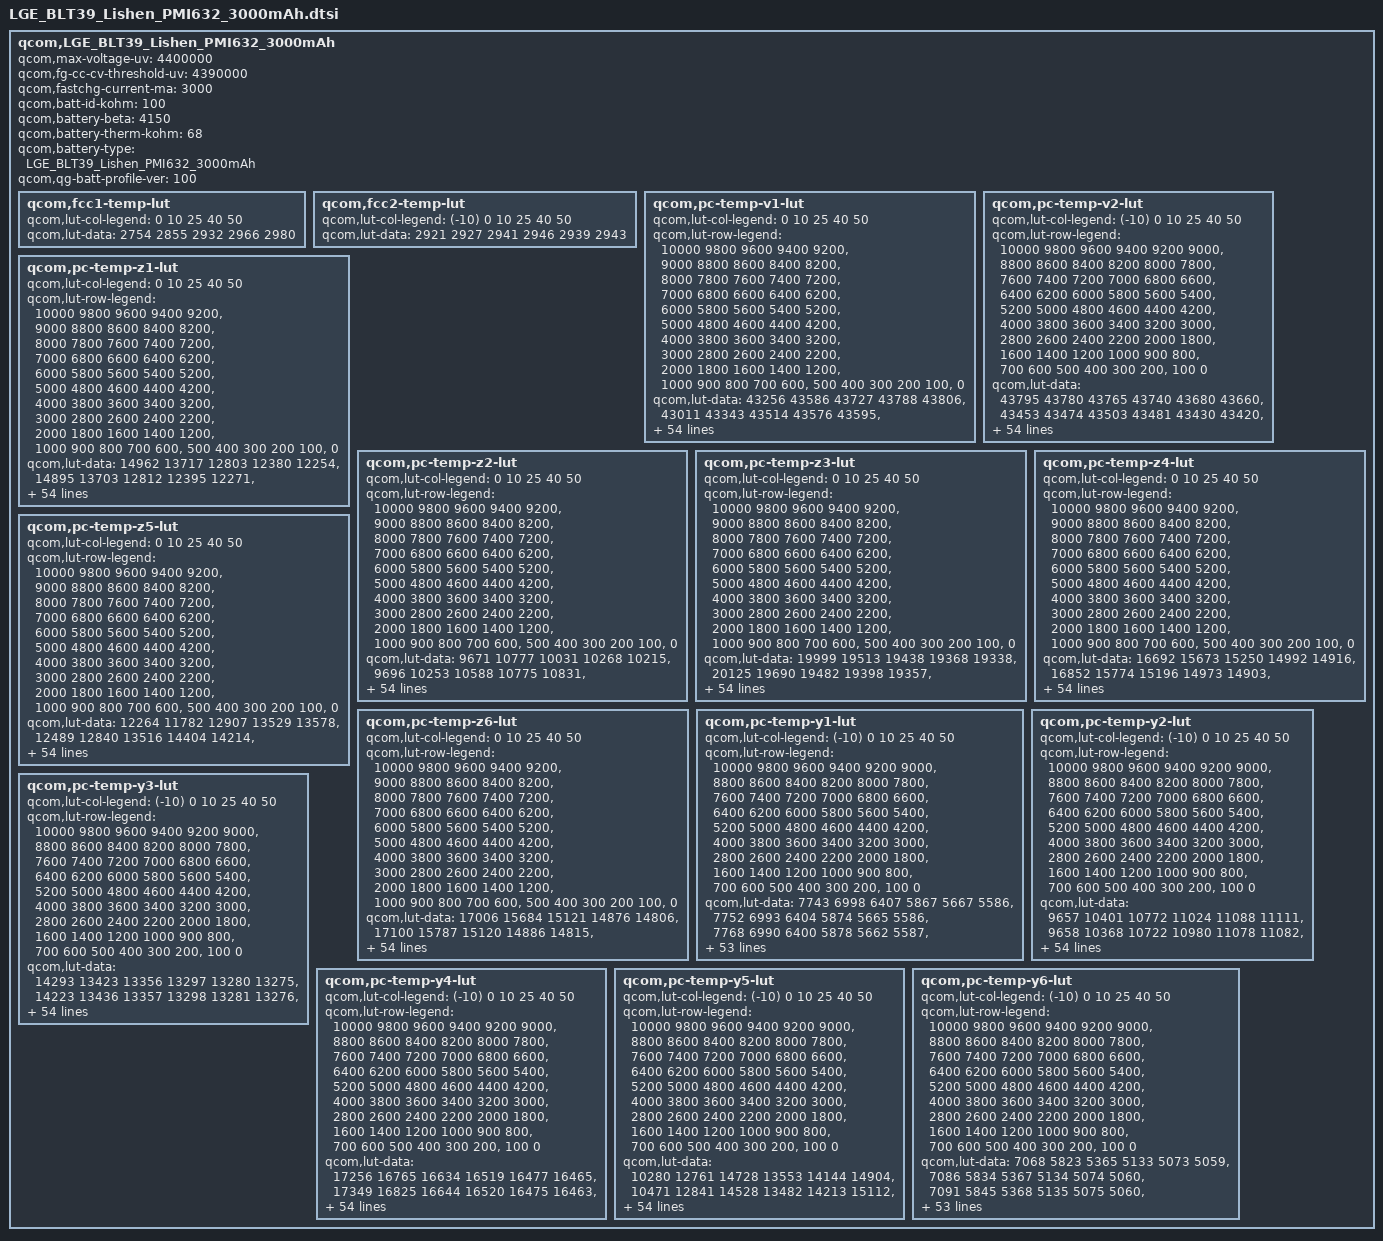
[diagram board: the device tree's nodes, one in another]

qcom,LGE_BLT39_Lishen_PMI632_3000mAh {
    /* 3840735_LGE_BLT39lish_3000mAh_averaged_MasterSlave_Feb14th2019 */
    qcom,max-voltage-uv = <4400000>;
    qcom,fg-cc-cv-threshold-uv = <4390000>;
    qcom,fastchg-current-ma = <3000>;
    qcom,batt-id-kohm = <100>;
    qcom,battery-beta = <4150>;
    qcom,battery-therm-kohm = <68>;
    qcom,battery-type = "LGE_BLT39_Lishen_PMI632_3000mAh";
    qcom,qg-batt-profile-ver = <100>;

	qcom,fcc1-temp-lut {
		qcom,lut-col-legend = <0 10 25 40 50>;
		qcom,lut-data = <2754 2855 2932 2966 2980>;
	};

	qcom,fcc2-temp-lut {
		qcom,lut-col-legend = <(-10) 0 10 25 40 50>;
		qcom,lut-data = <2921 2927 2941 2946 2939 2943>;
	};

	qcom,pc-temp-v1-lut {
		qcom,lut-col-legend = <0 10 25 40 50>;
		qcom,lut-row-legend = <10000 9800 9600 9400 9200>,
			<9000 8800 8600 8400 8200>,
			<8000 7800 7600 7400 7200>,
			<7000 6800 6600 6400 6200>,
			<6000 5800 5600 5400 5200>,
			<5000 4800 4600 4400 4200>,
			<4000 3800 3600 3400 3200>,
			<3000 2800 2600 2400 2200>,
			<2000 1800 1600 1400 1200>,
			<1000 900 800 700 600>,
			<500 400 300 200 100>,
			<0>;
		qcom,lut-data = <43256 43586 43727 43788 43806>,
			<43011 43343 43514 43576 43595>,
			<42778 43103 43291 43359 43380>,
			<42551 42865 43062 43136 43159>,
			<42326 42632 42829 42908 42933>,
			<42103 42401 42592 42678 42704>,
			<41883 42173 42355 42445 42472>,
			<41667 41950 42122 42212 42239>,
			<41454 41730 41894 41981 42010>,
			<41247 41513 41670 41751 41783>,
			<41048 41300 41451 41527 41559>,
			<40855 41097 41238 41310 41338>,
			<40668 40901 41030 41097 41121>,
			<40485 40712 40829 40892 40914>,
			<40309 40525 40634 40690 40713>,
			<40144 40341 40447 40499 40519>,
			<39990 40168 40268 40315 40332>,
			<39843 40008 40098 40139 40153>,
			<39696 39853 39946 39978 39985>,
			<39553 39699 39789 39824 39829>,
			<39416 39547 39595 39643 39656>,
			<39282 39385 39364 39410 39438>,
			<39154 39189 39158 39186 39219>,
			<39030 38974 38987 39019 39044>,
			<38907 38805 38837 38879 38891>,
			<38790 38679 38721 38755 38759>,
			<38682 38577 38627 38643 38645>,
			<38578 38501 38542 38542 38543>,
			<38488 38440 38456 38449 38448>,
			<38419 38385 38377 38361 38358>,
			<38362 38334 38307 38284 38276>,
			<38315 38287 38243 38214 38201>,
			<38277 38244 38187 38152 38132>,
			<38244 38206 38139 38097 38071>,
			<38213 38170 38097 38049 38019>,
			<38186 38138 38054 37999 37962>,
			<38155 38108 38016 37943 37894>,
			<38112 38068 37971 37882 37819>,
			<38049 37999 37905 37810 37743>,
			<37971 37908 37816 37728 37665>,
			<37874 37807 37717 37633 37575>,
			<37753 37688 37604 37522 37461>,
			<37616 37549 37472 37394 37329>,
			<37461 37385 37311 37235 37171>,
			<37302 37239 37170 37096 37034>,
			<37200 37143 37077 37006 36948>,
			<37161 37111 37052 36981 36924>,
			<37128 37084 37032 36964 36907>,
			<37097 37057 37012 36948 36894>,
			<37036 37012 36972 36908 36849>,
			<36839 36835 36762 36679 36602>,
			<36406 36404 36333 36258 36180>,
			<35833 35841 35774 35705 35625>,
			<35057 35077 35010 34950 34869>,
			<33794 33865 33819 33784 33706>,
			<30000 30000 30000 30000 30000>;
	};

	qcom,pc-temp-v2-lut {
		qcom,lut-col-legend = <(-10) 0 10 25 40 50>;
		qcom,lut-row-legend = <10000 9800 9600 9400 9200 9000>,
			<8800 8600 8400 8200 8000 7800>,
			<7600 7400 7200 7000 6800 6600>,
			<6400 6200 6000 5800 5600 5400>,
			<5200 5000 4800 4600 4400 4200>,
			<4000 3800 3600 3400 3200 3000>,
			<2800 2600 2400 2200 2000 1800>,
			<1600 1400 1200 1000 900 800>,
			<700 600 500 400 300 200>,
			<100 0>;
		qcom,lut-data = <43795 43780 43765 43740 43680 43660>,
			<43453 43474 43503 43481 43430 43420>,
			<43134 43187 43247 43229 43186 43184>,
			<42839 42922 43001 42987 42948 42951>,
			<42569 42677 42762 42754 42718 42722>,
			<42311 42440 42527 42523 42490 42493>,
			<42057 42203 42292 42291 42259 42263>,
			<41812 41968 42057 42059 42029 42033>,
			<41569 41740 41828 41830 41802 41807>,
			<41328 41518 41603 41605 41578 41583>,
			<41093 41300 41382 41383 41358 41363>,
			<40871 41088 41167 41168 41145 41149>,
			<40657 40882 40957 40958 40936 40938>,
			<40434 40677 40754 40755 40735 40736>,
			<40188 40471 40561 40555 40538 40541>,
			<39942 40263 40367 40363 40348 40352>,
			<39721 40044 40160 40182 40168 40172>,
			<39517 39816 39945 40010 39997 39997>,
			<39324 39598 39731 39830 39824 39824>,
			<39138 39395 39514 39640 39652 39657>,
			<38960 39204 39305 39444 39475 39484>,
			<38795 39020 39119 39234 39270 39280>,
			<38637 38844 38950 39009 39033 39043>,
			<38500 38686 38799 38824 38836 38847>,
			<38387 38553 38665 38689 38700 38710>,
			<38292 38434 38545 38575 38587 38597>,
			<38212 38322 38434 38468 38482 38490>,
			<38148 38213 38331 38369 38386 38391>,
			<38091 38119 38236 38278 38296 38300>,
			<38035 38047 38149 38191 38213 38216>,
			<37983 37988 38068 38112 38137 38139>,
			<37931 37934 37991 38040 38066 38067>,
			<37880 37883 37916 37977 38006 38004>,
			<37826 37834 37848 37914 37944 37937>,
			<37769 37785 37791 37850 37867 37854>,
			<37708 37737 37741 37784 37781 37758>,
			<37642 37684 37690 37713 37691 37658>,
			<37571 37624 37641 37634 37593 37549>,
			<37495 37556 37586 37553 37495 37444>,
			<37413 37480 37517 37474 37410 37356>,
			<37325 37391 37432 37395 37333 37277>,
			<37233 37290 37333 37302 37244 37184>,
			<37144 37164 37213 37180 37124 37064>,
			<37053 37030 37080 37052 37002 36941>,
			<36959 36909 36926 36916 36876 36820>,
			<36861 36807 36843 36871 36832 36782>,
			<36808 36765 36820 36853 36820 36769>,
			<36748 36721 36796 36833 36803 36751>,
			<36671 36667 36757 36799 36771 36718>,
			<36549 36575 36687 36699 36685 36610>,
			<36348 36382 36461 36416 36398 36293>,
			<36011 35995 36004 35900 35916 35797>,
			<35469 35402 35363 35233 35277 35144>,
			<34612 34545 34472 34266 34388 34228>,
			<33175 33107 33068 32862 32984 32797>,
			<28643 28622 29422 28756 29732 29552>;
	};

	qcom,pc-temp-z1-lut {
		qcom,lut-col-legend = <0 10 25 40 50>;
		qcom,lut-row-legend = <10000 9800 9600 9400 9200>,
			<9000 8800 8600 8400 8200>,
			<8000 7800 7600 7400 7200>,
			<7000 6800 6600 6400 6200>,
			<6000 5800 5600 5400 5200>,
			<5000 4800 4600 4400 4200>,
			<4000 3800 3600 3400 3200>,
			<3000 2800 2600 2400 2200>,
			<2000 1800 1600 1400 1200>,
			<1000 900 800 700 600>,
			<500 400 300 200 100>,
			<0>;
		qcom,lut-data = <14962 13717 12803 12380 12254>,
			<14895 13703 12812 12395 12271>,
			<14893 13710 12807 12403 12284>,
			<14898 13709 12801 12403 12291>,
			<14897 13705 12794 12404 12296>,
			<14894 13700 12787 12404 12299>,
			<14889 13692 12782 12404 12301>,
			<14881 13683 12782 12403 12302>,
			<14871 13678 12783 12402 12302>,
			<14859 13682 12783 12401 12303>,
			<14849 13691 12781 12400 12303>,
			<14838 13695 12777 12400 12303>,
			<14827 13685 12776 12400 12304>,
			<14808 13673 12777 12401 12304>,
			<14788 13671 12778 12402 12306>,
			<14779 13671 12779 12403 12307>,
			<14778 13671 12781 12405 12312>,
			<14781 13684 12783 12407 12316>,
			<14787 13704 12787 12409 12317>,
			<14799 13711 12793 12411 12316>,
			<14812 13707 12798 12414 12317>,
			<14828 13704 12803 12418 12320>,
			<14847 13714 12809 12422 12323>,
			<14856 13727 12814 12426 12327>,
			<14861 13736 12819 12429 12332>,
			<14865 13748 12826 12433 12336>,
			<14866 13762 12833 12438 12339>,
			<14864 13764 12840 12444 12343>,
			<14860 13762 12845 12448 12347>,
			<14855 13762 12850 12453 12351>,
			<14849 13771 12854 12457 12354>,
			<14848 13781 12858 12461 12357>,
			<14854 13785 12862 12465 12360>,
			<14866 13787 12868 12470 12363>,
			<14878 13789 12875 12476 12367>,
			<14905 13795 12882 12480 12370>,
			<14930 13805 12889 12483 12373>,
			<14933 13815 12896 12487 12376>,
			<14921 13824 12900 12490 12379>,
			<14912 13835 12904 12494 12382>,
			<14920 13845 12908 12498 12385>,
			<14932 13861 12914 12501 12388>,
			<14923 13868 12920 12505 12392>,
			<14905 13868 12927 12509 12395>,
			<14906 13867 12940 12513 12400>,
			<14885 13896 12944 12517 12401>,
			<14898 13871 12947 12518 12403>,
			<14921 13860 12945 12522 12403>,
			<14913 13863 12945 12523 12407>,
			<14906 13868 12955 12529 12409>,
			<14948 13891 12965 12535 12416>,
			<14968 13925 12986 12548 12427>,
			<14933 13968 13004 12567 12441>,
			<14956 13992 13050 12590 12462>,
			<14956 13992 13050 12590 12462>,
			<14956 13992 13050 12590 12462>;
	};

	qcom,pc-temp-z2-lut {
		qcom,lut-col-legend = <0 10 25 40 50>;
		qcom,lut-row-legend = <10000 9800 9600 9400 9200>,
			<9000 8800 8600 8400 8200>,
			<8000 7800 7600 7400 7200>,
			<7000 6800 6600 6400 6200>,
			<6000 5800 5600 5400 5200>,
			<5000 4800 4600 4400 4200>,
			<4000 3800 3600 3400 3200>,
			<3000 2800 2600 2400 2200>,
			<2000 1800 1600 1400 1200>,
			<1000 900 800 700 600>,
			<500 400 300 200 100>,
			<0>;
		qcom,lut-data = <9671 10777 10031 10268 10215>,
			<9696 10253 10588 10775 10831>,
			<9702 9913 10638 11001 11158>,
			<9705 9833 10485 10911 11107>,
			<9706 9812 10322 10748 10926>,
			<9700 9796 10173 10670 10853>,
			<9691 9784 10047 10640 10837>,
			<9684 9774 10042 10603 10817>,
			<9677 9769 10162 10484 10778>,
			<9669 9774 10262 10325 10721>,
			<9660 9785 10281 10302 10702>,
			<9651 9807 10293 10431 10711>,
			<9645 9866 10296 10545 10722>,
			<9641 9909 10281 10570 10640>,
			<9638 9894 10268 10592 10409>,
			<9645 9859 10278 10614 10314>,
			<9699 9852 10300 10660 10316>,
			<9749 9868 10307 10694 10320>,
			<9738 9888 10229 10589 10331>,
			<9686 9902 10145 10352 10357>,
			<9654 9913 10141 10272 10371>,
			<9657 9922 10151 10291 10365>,
			<9664 9930 10154 10318 10356>,
			<9672 9937 10126 10352 10358>,
			<9682 9943 10089 10393 10369>,
			<9696 9949 10091 10404 10363>,
			<9708 9952 10129 10362 10300>,
			<9722 9952 10152 10307 10227>,
			<9735 9950 10130 10273 10205>,
			<9747 9948 10096 10246 10195>,
			<9759 9951 10088 10228 10191>,
			<9770 9956 10093 10215 10203>,
			<9780 9962 10099 10207 10225>,
			<9791 9967 10109 10206 10248>,
			<9804 9974 10121 10208 10279>,
			<9822 9981 10133 10214 10313>,
			<9841 9991 10145 10264 10365>,
			<9862 10000 10156 10329 10413>,
			<9886 10011 10169 10358 10421>,
			<9904 10021 10183 10384 10413>,
			<9831 10027 10196 10394 10410>,
			<9696 10029 10209 10370 10429>,
			<9627 10035 10216 10347 10445>,
			<9614 10051 10215 10344 10443>,
			<10127 10191 10244 10377 10454>,
			<12074 10313 10264 10403 10458>,
			<10518 10457 10259 10370 10496>,
			<10377 10558 10263 10421 10452>,
			<10513 10600 10253 10429 10496>,
			<10772 10645 10282 10483 10578>,
			<10680 10605 10436 10435 10399>,
			<9724 10364 10495 10373 10311>,
			<9463 10198 10534 10410 10294>,
			<9304 10026 10385 10349 10182>,
			<9304 10026 10385 10349 10182>,
			<9304 10026 10385 10349 10182>;
	};

	qcom,pc-temp-z3-lut {
		qcom,lut-col-legend = <0 10 25 40 50>;
		qcom,lut-row-legend = <10000 9800 9600 9400 9200>,
			<9000 8800 8600 8400 8200>,
			<8000 7800 7600 7400 7200>,
			<7000 6800 6600 6400 6200>,
			<6000 5800 5600 5400 5200>,
			<5000 4800 4600 4400 4200>,
			<4000 3800 3600 3400 3200>,
			<3000 2800 2600 2400 2200>,
			<2000 1800 1600 1400 1200>,
			<1000 900 800 700 600>,
			<500 400 300 200 100>,
			<0>;
		qcom,lut-data = <19999 19513 19438 19368 19338>,
			<20125 19690 19482 19398 19357>,
			<20113 19791 19513 19420 19376>,
			<20090 19823 19544 19442 19397>,
			<20078 19835 19559 19461 19420>,
			<20071 19841 19558 19464 19427>,
			<20067 19839 19557 19461 19426>,
			<20071 19827 19557 19456 19422>,
			<20089 19813 19561 19445 19415>,
			<20102 19799 19563 19429 19403>,
			<20103 19785 19558 19422 19398>,
			<20101 19777 19552 19421 19398>,
			<20098 19775 19545 19421 19397>,
			<20086 19773 19533 19420 19387>,
			<20069 19756 19523 19419 19361>,
			<20060 19727 19520 19416 19350>,
			<20057 19706 19518 19409 19349>,
			<20056 19689 19513 19401 19348>,
			<20042 19674 19490 19389 19346>,
			<20004 19672 19467 19374 19344>,
			<19981 19680 19476 19370 19343>,
			<19985 19692 19512 19386 19345>,
			<19998 19711 19530 19400 19351>,
			<20008 19734 19514 19397 19359>,
			<20019 19742 19492 19389 19372>,
			<20027 19741 19487 19388 19380>,
			<20029 19738 19488 19408 19383>,
			<20029 19734 19491 19428 19384>,
			<20028 19726 19502 19429 19383>,
			<20022 19718 19517 19425 19380>,
			<20005 19712 19520 19420 19376>,
			<19987 19706 19518 19411 19373>,
			<19969 19701 19516 19402 19369>,
			<19950 19696 19511 19395 19365>,
			<19929 19691 19505 19390 19359>,
			<19904 19685 19501 19389 19357>,
			<19878 19678 19498 19389 19357>,
			<19857 19672 19495 19389 19358>,
			<19840 19668 19490 19389 19358>,
			<19819 19663 19485 19387 19354>,
			<19713 19656 19481 19385 19352>,
			<19553 19644 19477 19379 19352>,
			<19423 19632 19472 19374 19353>,
			<19268 19619 19467 19372 19353>,
			<19262 19550 19450 19365 19346>,
			<19258 19464 19444 19360 19343>,
			<19261 19384 19431 19360 19342>,
			<19260 19337 19430 19359 19341>,
			<19260 19327 19414 19350 19325>,
			<19260 19321 19408 19338 19319>,
			<19261 19337 19383 19357 19342>,
			<19264 19334 19367 19358 19347>,
			<19270 19329 19350 19344 19348>,
			<19278 19333 19370 19352 19355>,
			<19278 19333 19370 19352 19355>,
			<19278 19333 19370 19352 19355>;
	};

	qcom,pc-temp-z4-lut {
		qcom,lut-col-legend = <0 10 25 40 50>;
		qcom,lut-row-legend = <10000 9800 9600 9400 9200>,
			<9000 8800 8600 8400 8200>,
			<8000 7800 7600 7400 7200>,
			<7000 6800 6600 6400 6200>,
			<6000 5800 5600 5400 5200>,
			<5000 4800 4600 4400 4200>,
			<4000 3800 3600 3400 3200>,
			<3000 2800 2600 2400 2200>,
			<2000 1800 1600 1400 1200>,
			<1000 900 800 700 600>,
			<500 400 300 200 100>,
			<0>;
		qcom,lut-data = <16692 15673 15250 14992 14916>,
			<16852 15774 15196 14973 14903>,
			<16715 15610 15128 14946 14884>,
			<16427 15455 15042 14905 14856>,
			<16191 15330 14973 14857 14817>,
			<16016 15224 14932 14820 14787>,
			<15860 15146 14899 14789 14763>,
			<15724 15085 14864 14769 14747>,
			<15600 15033 14820 14768 14742>,
			<15495 14986 14784 14773 14739>,
			<15409 14944 14764 14771 14734>,
			<15337 14906 14750 14753 14721>,
			<15278 14866 14744 14733 14708>,
			<15233 14843 14743 14721 14711>,
			<15193 14848 14742 14708 14725>,
			<15146 14863 14735 14701 14729>,
			<15071 14866 14724 14697 14720>,
			<15012 14862 14720 14694 14708>,
			<15010 14856 14730 14694 14701>,
			<15037 14846 14747 14702 14695>,
			<15048 14828 14770 14721 14696>,
			<15025 14817 14812 14793 14760>,
			<14993 14849 14855 14859 14834>,
			<14974 14924 14904 14874 14840>,
			<14962 14962 14943 14882 14832>,
			<14953 14972 14942 14881 14821>,
			<14954 14975 14910 14840 14801>,
			<14963 14966 14873 14790 14778>,
			<14972 14942 14838 14768 14761>,
			<14971 14917 14803 14752 14747>,
			<14967 14898 14784 14742 14734>,
			<14962 14881 14772 14734 14722>,
			<14954 14866 14765 14728 14712>,
			<14943 14852 14761 14723 14706>,
			<14932 14840 14758 14718 14701>,
			<14921 14826 14757 14717 14699>,
			<14909 14812 14756 14728 14717>,
			<14896 14804 14756 14742 14741>,
			<14881 14800 14760 14746 14744>,
			<14870 14798 14769 14748 14739>,
			<14958 14792 14772 14749 14732>,
			<15114 14781 14754 14739 14720>,
			<15227 14773 14740 14732 14712>,
			<15355 14765 14735 14734 14713>,
			<15215 14758 14719 14725 14709>,
			<15204 14824 14701 14711 14698>,
			<15197 14905 14699 14695 14684>,
			<15190 14952 14683 14674 14665>,
			<15183 14955 14689 14664 14656>,
			<15175 14957 14693 14675 14662>,
			<15179 14943 14742 14685 14666>,
			<15213 14969 14766 14686 14663>,
			<15246 14987 14788 14702 14662>,
			<15284 15005 14772 14695 14656>,
			<15284 15005 14772 14695 14656>,
			<15284 15005 14772 14695 14656>;
	};

	qcom,pc-temp-z5-lut {
		qcom,lut-col-legend = <0 10 25 40 50>;
		qcom,lut-row-legend = <10000 9800 9600 9400 9200>,
			<9000 8800 8600 8400 8200>,
			<8000 7800 7600 7400 7200>,
			<7000 6800 6600 6400 6200>,
			<6000 5800 5600 5400 5200>,
			<5000 4800 4600 4400 4200>,
			<4000 3800 3600 3400 3200>,
			<3000 2800 2600 2400 2200>,
			<2000 1800 1600 1400 1200>,
			<1000 900 800 700 600>,
			<500 400 300 200 100>,
			<0>;
		qcom,lut-data = <12264 11782 12907 13529 13578>,
			<12489 12840 13516 14404 14214>,
			<12622 13689 13966 15100 14922>,
			<12733 14244 14593 15860 15877>,
			<12872 14649 15203 16862 17216>,
			<13059 14969 15640 17564 18253>,
			<13283 15204 16066 18308 19242>,
			<13566 15372 16780 18751 19891>,
			<13965 15584 18229 18387 19644>,
			<14355 16012 19529 17636 18895>,
			<14668 16609 20255 17481 18654>,
			<14946 17201 20795 17981 19649>,
			<15105 18077 20897 18741 20676>,
			<15181 18629 20661 19688 19743>,
			<15238 18276 20445 20754 16952>,
			<15385 17656 20863 21328 15805>,
			<16114 17465 21938 21515 16150>,
			<16755 17362 22266 21554 16670>,
			<16524 17226 20286 20446 17111>,
			<15724 17464 18140 17988 17561>,
			<15370 19206 20763 17499 17719>,
			<15970 21754 30080 19538 17444>,
			<17142 25948 34729 21333 16955>,
			<18512 31242 29025 19847 16300>,
			<20362 32953 21078 16026 15344>,
			<22426 31300 18577 14678 14941>,
			<24186 28837 17528 15764 15275>,
			<25974 26999 17132 17265 15869>,
			<27141 25258 18155 18383 16462>,
			<27179 24212 20233 19416 17163>,
			<26671 23868 22047 20052 17988>,
			<26073 23738 23829 20382 19072>,
			<25248 23872 25312 20686 20248>,
			<24115 24274 26343 21239 21308>,
			<23028 24707 27150 22137 22380>,
			<21848 24954 27587 22721 22829>,
			<20829 25130 27874 23007 22399>,
			<20283 25397 28026 23177 21580>,
			<19964 26282 27402 22868 20666>,
			<19565 27241 25705 21551 19454>,
			<17719 26943 24708 20329 18866>,
			<15044 24655 24452 19579 19037>,
			<13057 23333 24073 18839 19184>,
			<10740 22637 22857 17843 18377>,
			<10920 19806 22228 17491 17462>,
			<10871 14385 22765 17436 17386>,
			<10867 12278 20374 18262 18088>,
			<10865 11513 20158 19682 20107>,
			<10865 11417 17651 19193 18371>,
			<10878 11364 17209 16421 16837>,
			<10884 11559 14326 16414 16885>,
			<10837 11420 13177 15975 17290>,
			<10752 11291 12484 14072 17052>,
			<10701 11219 12878 14438 18093>,
			<10701 11219 12878 14438 18093>,
			<10701 11219 12878 14438 18093>;
	};

	qcom,pc-temp-z6-lut {
		qcom,lut-col-legend = <0 10 25 40 50>;
		qcom,lut-row-legend = <10000 9800 9600 9400 9200>,
			<9000 8800 8600 8400 8200>,
			<8000 7800 7600 7400 7200>,
			<7000 6800 6600 6400 6200>,
			<6000 5800 5600 5400 5200>,
			<5000 4800 4600 4400 4200>,
			<4000 3800 3600 3400 3200>,
			<3000 2800 2600 2400 2200>,
			<2000 1800 1600 1400 1200>,
			<1000 900 800 700 600>,
			<500 400 300 200 100>,
			<0>;
		qcom,lut-data = <17006 15684 15121 14876 14806>,
			<17100 15787 15120 14886 14815>,
			<17021 15753 15110 14890 14820>,
			<16854 15711 15085 14884 14819>,
			<16720 15654 15059 14872 14814>,
			<16620 15593 15039 14861 14809>,
			<16534 15546 15020 14846 14799>,
			<16466 15505 15003 14833 14789>,
			<16409 15469 14985 14825 14781>,
			<16360 15435 14970 14819 14775>,
			<16315 15406 14959 14812 14769>,
			<16274 15384 14950 14804 14763>,
			<16236 15367 14942 14796 14758>,
			<16198 15353 14935 14790 14752>,
			<16163 15343 14928 14785 14745>,
			<16132 15333 14923 14779 14739>,
			<16098 15325 14918 14774 14734>,
			<16075 15314 14914 14769 14730>,
			<16068 15305 14908 14765 14726>,
			<16064 15304 14904 14761 14723>,
			<16062 15304 14915 14763 14722>,
			<16061 15305 14956 14803 14751>,
			<16060 15328 14985 14841 14787>,
			<16060 15376 14999 14846 14797>,
			<16063 15401 15007 14848 14801>,
			<16068 15407 15005 14848 14802>,
			<16074 15411 14993 14842 14797>,
			<16085 15408 14982 14832 14787>,
			<16092 15396 14974 14824 14779>,
			<16090 15384 14968 14816 14772>,
			<16082 15375 14963 14808 14765>,
			<16074 15367 14958 14800 14758>,
			<16067 15360 14954 14794 14752>,
			<16061 15354 14950 14788 14746>,
			<16053 15349 14947 14784 14741>,
			<16043 15344 14946 14782 14739>,
			<16032 15339 14946 14788 14748>,
			<16023 15337 14946 14795 14759>,
			<16015 15339 14947 14796 14760>,
			<16009 15342 14950 14797 14756>,
			<16003 15341 14951 14797 14752>,
			<15998 15336 14943 14790 14748>,
			<15989 15333 14937 14785 14745>,
			<15969 15331 14935 14785 14746>,
			<15915 15302 14921 14779 14742>,
			<15918 15296 14914 14771 14735>,
			<15918 15293 14906 14764 14729>,
			<15919 15292 14901 14755 14720>,
			<15922 15293 14897 14746 14708>,
			<15930 15296 14899 14745 14708>,
			<15950 15312 14912 14761 14724>,
			<15985 15337 14920 14765 14727>,
			<16029 15362 14929 14769 14731>,
			<16085 15401 14943 14775 14736>,
			<16085 15401 14943 14775 14736>,
			<16085 15401 14943 14775 14736>;
	};

	qcom,pc-temp-y1-lut {
		qcom,lut-col-legend = <(-10) 0 10 25 40 50>;
		qcom,lut-row-legend = <10000 9800 9600 9400 9200 9000>,
			<8800 8600 8400 8200 8000 7800>,
			<7600 7400 7200 7000 6800 6600>,
			<6400 6200 6000 5800 5600 5400>,
			<5200 5000 4800 4600 4400 4200>,
			<4000 3800 3600 3400 3200 3000>,
			<2800 2600 2400 2200 2000 1800>,
			<1600 1400 1200 1000 900 800>,
			<700 600 500 400 300 200>,
			<100 0>;
		qcom,lut-data = <7743 6998 6407 5867 5667 5586>,
			<7752 6993 6404 5874 5665 5586>,
			<7768 6990 6400 5878 5662 5587>,
			<7785 6988 6395 5880 5659 5586>,
			<7799 6988 6390 5881 5657 5586>,
			<7806 6989 6388 5881 5656 5586>,
			<7806 6994 6387 5879 5654 5585>,
			<7804 7003 6386 5876 5653 5584>,
			<7803 7008 6386 5873 5653 5584>,
			<7803 7016 6389 5872 5653 5584>,
			<7802 7022 6391 5870 5654 5584>,
			<7796 7017 6390 5871 5652 5583>,
			<7784 7002 6389 5871 5650 5583>,
			<7779 6996 6388 5871 5649 5583>,
			<7797 6998 6385 5870 5650 5584>,
			<7817 7002 6382 5870 5651 5586>,
			<7814 7009 6383 5870 5651 5586>,
			<7791 7029 6383 5870 5651 5585>,
			<7775 7039 6384 5872 5651 5584>,
			<7781 7037 6384 5875 5651 5585>,
			<7790 7033 6385 5878 5652 5586>,
			<7790 7029 6387 5878 5653 5587>,
			<7777 7025 6396 5879 5654 5588>,
			<7767 7024 6403 5879 5656 5589>,
			<7775 7029 6409 5882 5658 5590>,
			<7791 7035 6413 5886 5660 5591>,
			<7794 7040 6415 5888 5661 5592>,
			<7778 7043 6415 5890 5662 5595>,
			<7763 7045 6414 5891 5663 5597>,
			<7774 7040 6412 5895 5665 5597>,
			<7802 7031 6408 5899 5667 5598>,
			<7813 7029 6407 5901 5669 5599>,
			<7816 7047 6404 5901 5672 5603>,
			<7817 7063 6401 5901 5675 5606>,
			<7813 7057 6402 5905 5678 5607>,
			<7805 7044 6405 5913 5681 5608>,
			<7796 7034 6408 5915 5683 5608>,
			<7778 7022 6415 5917 5685 5611>,
			<7759 7011 6422 5919 5687 5614>,
			<7757 7013 6422 5923 5689 5616>,
			<7767 7022 6420 5929 5691 5618>,
			<7775 7028 6421 5933 5693 5619>,
			<7778 7028 6428 5934 5695 5620>,
			<7784 7030 6433 5935 5697 5621>,
			<7780 7019 6434 5938 5701 5626>,
			<7778 7025 6434 5942 5704 5626>,
			<7782 7039 6435 5947 5705 5627>,
			<7798 7044 6438 5951 5706 5630>,
			<7824 7039 6442 5951 5707 5630>,
			<7802 7067 6446 5950 5707 5632>,
			<7824 7067 6463 5956 5712 5633>,
			<7912 7069 6481 5971 5720 5642>,
			<8009 7120 6496 5998 5730 5653>,
			<8164 7203 6531 6015 5748 5667>,
			<8164 7203 6531 6015 5748 5667>,
			<8164 7203 6531 6015 5748 5667>;
	};

	qcom,pc-temp-y2-lut {
		qcom,lut-col-legend = <(-10) 0 10 25 40 50>;
		qcom,lut-row-legend = <10000 9800 9600 9400 9200 9000>,
			<8800 8600 8400 8200 8000 7800>,
			<7600 7400 7200 7000 6800 6600>,
			<6400 6200 6000 5800 5600 5400>,
			<5200 5000 4800 4600 4400 4200>,
			<4000 3800 3600 3400 3200 3000>,
			<2800 2600 2400 2200 2000 1800>,
			<1600 1400 1200 1000 900 800>,
			<700 600 500 400 300 200>,
			<100 0>;
		qcom,lut-data = <9657 10401 10772 11024 11088 11111>,
			<9658 10368 10722 10980 11078 11082>,
			<9658 10346 10668 10938 11052 11041>,
			<9659 10331 10615 10899 11018 10997>,
			<9660 10323 10569 10864 10982 10960>,
			<9661 10320 10537 10835 10952 10938>,
			<9661 10324 10516 10813 10918 10931>,
			<9662 10335 10500 10794 10881 10926>,
			<9663 10348 10494 10779 10873 10925>,
			<9663 10367 10493 10765 10880 10916>,
			<9663 10388 10494 10754 10889 10909>,
			<9663 10410 10501 10741 10893 10899>,
			<9663 10433 10517 10730 10893 10879>,
			<9663 10456 10537 10724 10890 10876>,
			<9662 10481 10567 10723 10871 10904>,
			<9662 10502 10597 10724 10853 10934>,
			<9661 10512 10616 10738 10860 10938>,
			<9660 10518 10630 10772 10893 10928>,
			<9659 10525 10644 10796 10933 10932>,
			<9659 10538 10660 10807 10999 11024>,
			<9659 10552 10677 10818 11060 11127>,
			<9659 10514 10692 10837 11056 11134>,
			<9659 10302 10708 10867 11010 11112>,
			<9658 10160 10723 10887 10983 11096>,
			<9658 10297 10743 10892 11000 11094>,
			<9657 10530 10761 10897 11027 11096>,
			<9657 10547 10770 10905 11044 11103>,
			<9656 10189 10776 10919 11078 11141>,
			<9656 9865 10779 10926 11100 11169>,
			<9655 9818 10777 10922 11082 11185>,
			<9655 9796 10773 10913 11052 11208>,
			<9655 9800 10771 10908 11059 11213>,
			<9654 9966 10772 10907 11126 11223>,
			<9654 10147 10774 10907 11180 11232>,
			<9654 10088 10772 10904 11149 11235>,
			<9653 9836 10770 10897 11076 11236>,
			<9653 9696 10764 10888 11043 11231>,
			<9653 9681 10736 10871 11033 11197>,
			<9653 9673 10700 10857 11029 11165>,
			<9653 9667 10673 10866 11044 11172>,
			<9653 9664 10647 10888 11079 11195>,
			<9653 9661 10612 10898 11107 11203>,
			<9652 9658 10562 10897 11129 11184>,
			<9652 9656 10493 10883 11136 11154>,
			<9652 9655 10328 10817 11055 11100>,
			<9652 9654 10202 10821 11046 11039>,
			<9652 9653 10223 10849 11047 11018>,
			<9652 9653 10280 10860 11010 11014>,
			<9652 9653 10181 10835 10982 10948>,
			<9651 9652 10201 10829 10938 10917>,
			<9651 9651 9811 10776 10974 10930>,
			<9650 9651 9702 10744 10896 10834>,
			<9648 9650 9668 10654 10853 10783>,
			<9647 9649 9658 10556 10758 10702>,
			<9647 9649 9658 10556 10758 10702>,
			<9647 9649 9658 10556 10758 10702>;
	};

	qcom,pc-temp-y3-lut {
		qcom,lut-col-legend = <(-10) 0 10 25 40 50>;
		qcom,lut-row-legend = <10000 9800 9600 9400 9200 9000>,
			<8800 8600 8400 8200 8000 7800>,
			<7600 7400 7200 7000 6800 6600>,
			<6400 6200 6000 5800 5600 5400>,
			<5200 5000 4800 4600 4400 4200>,
			<4000 3800 3600 3400 3200 3000>,
			<2800 2600 2400 2200 2000 1800>,
			<1600 1400 1200 1000 900 800>,
			<700 600 500 400 300 200>,
			<100 0>;
		qcom,lut-data = <14293 13423 13356 13297 13280 13275>,
			<14223 13436 13357 13298 13281 13276>,
			<14155 13451 13360 13300 13282 13278>,
			<14092 13466 13362 13301 13283 13279>,
			<14037 13478 13365 13303 13284 13280>,
			<13991 13487 13367 13304 13285 13281>,
			<13958 13492 13370 13305 13286 13282>,
			<13930 13496 13372 13305 13287 13283>,
			<13899 13496 13373 13306 13287 13283>,
			<13860 13496 13375 13307 13287 13283>,
			<13827 13494 13377 13308 13286 13283>,
			<13814 13491 13378 13311 13288 13283>,
			<13805 13487 13381 13317 13293 13283>,
			<13794 13482 13383 13319 13295 13283>,
			<13763 13479 13386 13319 13293 13286>,
			<13724 13475 13389 13319 13292 13290>,
			<13693 13468 13388 13320 13293 13289>,
			<13664 13457 13383 13323 13297 13288>,
			<13647 13447 13378 13324 13299 13288>,
			<13640 13439 13372 13324 13301 13291>,
			<13636 13431 13366 13323 13302 13295>,
			<13631 13418 13359 13319 13299 13293>,
			<13626 13394 13352 13309 13289 13284>,
			<13624 13378 13348 13303 13282 13278>,
			<13629 13383 13345 13304 13281 13277>,
			<13644 13392 13342 13306 13281 13276>,
			<13664 13384 13342 13305 13281 13276>,
			<13696 13321 13341 13304 13283 13277>,
			<13737 13269 13341 13303 13284 13278>,
			<13782 13267 13341 13303 13284 13278>,
			<13835 13269 13342 13302 13284 13278>,
			<13894 13274 13342 13303 13284 13278>,
			<13959 13313 13338 13306 13286 13278>,
			<14030 13360 13335 13309 13287 13278>,
			<14108 13378 13334 13309 13287 13278>,
			<14193 13390 13335 13308 13286 13278>,
			<14281 13401 13336 13308 13285 13277>,
			<14374 13413 13340 13307 13284 13277>,
			<14468 13428 13345 13305 13282 13277>,
			<14555 13455 13348 13305 13282 13276>,
			<14637 13506 13350 13304 13281 13276>,
			<14717 13570 13352 13303 13281 13276>,
			<14795 13646 13355 13302 13281 13277>,
			<14878 13747 13357 13303 13282 13278>,
			<14979 13897 13348 13304 13283 13277>,
			<15121 14123 13357 13306 13284 13278>,
			<15212 14249 13366 13306 13284 13280>,
			<15198 14277 13371 13306 13287 13284>,
			<15279 14412 13379 13312 13293 13289>,
			<15531 14636 13399 13313 13294 13287>,
			<15868 14922 13408 13313 13288 13284>,
			<16540 15276 13447 13310 13289 13286>,
			<18625 15715 13554 13323 13291 13289>,
			<25299 17056 13812 13334 13298 13291>,
			<25299 17056 13812 13334 13298 13291>,
			<25299 17056 13812 13334 13298 13291>;
	};

	qcom,pc-temp-y4-lut {
		qcom,lut-col-legend = <(-10) 0 10 25 40 50>;
		qcom,lut-row-legend = <10000 9800 9600 9400 9200 9000>,
			<8800 8600 8400 8200 8000 7800>,
			<7600 7400 7200 7000 6800 6600>,
			<6400 6200 6000 5800 5600 5400>,
			<5200 5000 4800 4600 4400 4200>,
			<4000 3800 3600 3400 3200 3000>,
			<2800 2600 2400 2200 2000 1800>,
			<1600 1400 1200 1000 900 800>,
			<700 600 500 400 300 200>,
			<100 0>;
		qcom,lut-data = <17256 16765 16634 16519 16477 16465>,
			<17349 16825 16644 16520 16475 16463>,
			<17498 16892 16655 16521 16475 16462>,
			<17659 16958 16666 16522 16475 16461>,
			<17793 17015 16676 16524 16477 16461>,
			<17857 17052 16685 16527 16479 16461>,
			<17851 17070 16691 16531 16481 16462>,
			<17835 17082 16698 16537 16485 16465>,
			<17820 17095 16706 16544 16489 16469>,
			<17806 17109 16719 16551 16497 16473>,
			<17789 17125 16735 16559 16503 16479>,
			<17759 17149 16755 16564 16507 16486>,
			<17711 17178 16782 16570 16509 16495>,
			<17652 17188 16811 16579 16513 16501>,
			<17572 17182 16855 16597 16526 16505>,
			<17488 17168 16888 16623 16543 16509>,
			<17431 17136 16884 16655 16559 16519>,
			<17389 17062 16862 16697 16575 16536>,
			<17342 16990 16832 16716 16594 16555>,
			<17275 16929 16771 16717 16629 16586>,
			<17200 16877 16701 16713 16661 16612>,
			<17139 16852 16660 16678 16642 16594>,
			<17083 16842 16629 16577 16548 16520>,
			<17045 16833 16612 16518 16490 16477>,
			<17028 16788 16604 16508 16486 16475>,
			<17016 16723 16599 16503 16483 16474>,
			<17013 16718 16596 16504 16483 16474>,
			<17013 16809 16594 16510 16487 16477>,
			<17013 16888 16593 16517 16493 16482>,
			<17012 16892 16591 16524 16501 16489>,
			<17009 16890 16590 16532 16512 16501>,
			<17008 16883 16588 16541 16525 16512>,
			<17010 16819 16583 16552 16542 16527>,
			<17012 16754 16580 16558 16554 16536>,
			<17016 16760 16581 16557 16547 16529>,
			<17027 16801 16585 16553 16530 16511>,
			<17035 16835 16589 16545 16512 16496>,
			<17040 16857 16596 16518 16492 16482>,
			<17044 16872 16603 16497 16477 16473>,
			<17050 16876 16610 16497 16478 16473>,
			<17057 16877 16618 16500 16482 16475>,
			<17065 16877 16626 16503 16484 16476>,
			<17074 16872 16633 16508 16484 16474>,
			<17088 16867 16639 16508 16483 16470>,
			<17117 16880 16649 16494 16466 16458>,
			<17161 16918 16673 16509 16478 16471>,
			<17185 16946 16676 16524 16492 16480>,
			<17140 16949 16678 16539 16499 16487>,
			<17132 16988 16733 16558 16506 16500>,
			<17168 17071 16786 16566 16514 16501>,
			<17172 17123 16845 16542 16477 16462>,
			<17191 17099 16837 16538 16474 16460>,
			<17485 17099 16902 16560 16482 16472>,
			<19730 17444 17063 16636 16517 16522>,
			<19730 17444 17063 16636 16517 16522>,
			<19730 17444 17063 16636 16517 16522>;
	};

	qcom,pc-temp-y5-lut {
		qcom,lut-col-legend = <(-10) 0 10 25 40 50>;
		qcom,lut-row-legend = <10000 9800 9600 9400 9200 9000>,
			<8800 8600 8400 8200 8000 7800>,
			<7600 7400 7200 7000 6800 6600>,
			<6400 6200 6000 5800 5600 5400>,
			<5200 5000 4800 4600 4400 4200>,
			<4000 3800 3600 3400 3200 3000>,
			<2800 2600 2400 2200 2000 1800>,
			<1600 1400 1200 1000 900 800>,
			<700 600 500 400 300 200>,
			<100 0>;
		qcom,lut-data = <10280 12761 14728 13553 14144 14904>,
			<10471 12841 14528 13482 14213 15112>,
			<10654 12967 14288 13399 14213 15239>,
			<10829 13108 14037 13308 14157 15306>,
			<10993 13239 13806 13212 14061 15331>,
			<11146 13330 13624 13114 13937 15336>,
			<11300 13382 13425 12970 13781 15228>,
			<11444 13435 13178 12779 13578 14954>,
			<11518 13498 13029 12628 13335 14655>,
			<11544 13592 12853 12471 12969 14282>,
			<11573 13710 12728 12375 12716 13885>,
			<11791 13837 12742 12520 12932 13455>,
			<12285 13990 12813 12856 13477 13016>,
			<12494 14225 12944 12954 13654 12905>,
			<12280 14834 13459 12676 13113 13287>,
			<11978 15472 14182 12400 12543 13673>,
			<11825 15699 14907 12437 12534 13523>,
			<11721 15821 15731 12665 12708 13005>,
			<11661 15914 16243 13057 12984 12796>,
			<11637 16021 16536 14657 13963 13575>,
			<11616 16108 16722 16302 15018 14604>,
			<11549 15834 16558 16234 15076 14985>,
			<11311 14375 15803 15382 14735 15214>,
			<11061 13317 15209 14943 14506 15287>,
			<10881 13779 15005 15443 14414 15043>,
			<10731 14661 14932 16109 14319 14731>,
			<10692 14489 14932 16126 14375 14708>,
			<10692 12323 14937 15709 14723 14777>,
			<10692 10526 14974 15377 14975 14787>,
			<10715 10457 15238 15212 14878 14687>,
			<10779 10462 15626 15092 14725 14554>,
			<10837 10510 15643 15336 14850 14471>,
			<10927 11115 15024 16528 15343 14415>,
			<11022 11750 14438 17539 15887 14418>,
			<11061 11734 14297 17826 16330 14859>,
			<11078 11478 14256 18010 16731 15703>,
			<11074 11349 14360 18122 16824 16053>,
			<11060 11365 15063 18120 16510 16112>,
			<11043 11395 15740 18004 16057 16078>,
			<11007 11462 15736 17541 15599 15714>,
			<10917 11613 15500 16672 15018 14966>,
			<10859 11699 15379 16040 14650 14612>,
			<10905 11540 15281 15561 14424 14718>,
			<10984 11310 15052 15464 14386 15029>,
			<11048 11189 13240 16080 15875 15964>,
			<11175 11208 12979 15635 14815 14636>,
			<11305 11306 13466 14795 13866 14150>,
			<11382 11308 13706 14451 14110 14875>,
			<11519 11484 13398 14872 15330 16206>,
			<11562 11591 13880 14679 15229 15503>,
			<11639 11700 12252 15160 14885 16335>,
			<11471 11563 11661 14701 15608 18238>,
			<10537 11357 11625 16787 15994 19618>,
			<9472 10600 11505 17044 18427 19432>,
			<9472 10600 11505 17044 18427 19432>,
			<9472 10600 11505 17044 18427 19432>;
	};

	qcom,pc-temp-y6-lut {
		qcom,lut-col-legend = <(-10) 0 10 25 40 50>;
		qcom,lut-row-legend = <10000 9800 9600 9400 9200 9000>,
			<8800 8600 8400 8200 8000 7800>,
			<7600 7400 7200 7000 6800 6600>,
			<6400 6200 6000 5800 5600 5400>,
			<5200 5000 4800 4600 4400 4200>,
			<4000 3800 3600 3400 3200 3000>,
			<2800 2600 2400 2200 2000 1800>,
			<1600 1400 1200 1000 900 800>,
			<700 600 500 400 300 200>,
			<100 0>;
		qcom,lut-data = <7068 5823 5365 5133 5073 5059>,
			<7086 5834 5367 5134 5074 5060>,
			<7091 5845 5368 5135 5075 5060>,
			<7085 5855 5368 5136 5076 5061>,
			<7072 5863 5369 5137 5077 5062>,
			<7054 5866 5368 5138 5078 5063>,
			<7029 5865 5368 5139 5079 5064>,
			<6995 5862 5367 5141 5081 5065>,
			<6964 5859 5366 5143 5082 5067>,
			<6934 5855 5368 5145 5084 5068>,
			<6906 5851 5370 5147 5086 5070>,
			<6880 5849 5374 5151 5089 5072>,
			<6856 5848 5381 5156 5092 5074>,
			<6827 5846 5388 5161 5095 5076>,
			<6784 5840 5400 5166 5098 5079>,
			<6739 5831 5409 5172 5102 5083>,
			<6709 5815 5407 5183 5107 5086>,
			<6686 5785 5397 5197 5114 5090>,
			<6666 5758 5383 5203 5121 5096>,
			<6646 5738 5361 5202 5132 5106>,
			<6629 5719 5336 5200 5142 5116>,
			<6616 5701 5320 5187 5134 5110>,
			<6606 5682 5307 5151 5100 5082>,
			<6601 5670 5300 5131 5078 5065>,
			<6607 5669 5297 5129 5076 5063>,
			<6623 5668 5295 5129 5076 5063>,
			<6643 5669 5295 5129 5076 5063>,
			<6671 5669 5296 5130 5078 5064>,
			<6705 5669 5297 5132 5081 5066>,
			<6744 5675 5299 5134 5083 5069>,
			<6788 5691 5302 5137 5087 5072>,
			<6836 5709 5302 5141 5091 5076>,
			<6887 5730 5302 5147 5097 5080>,
			<6942 5754 5302 5151 5101 5083>,
			<7002 5785 5305 5151 5100 5081>,
			<7069 5823 5311 5150 5094 5076>,
			<7139 5866 5319 5149 5089 5071>,
			<7211 5917 5329 5142 5082 5067>,
			<7285 5975 5342 5136 5077 5064>,
			<7353 6041 5355 5136 5077 5064>,
			<7415 6115 5369 5137 5078 5065>,
			<7477 6198 5387 5139 5079 5065>,
			<7540 6285 5410 5142 5080 5066>,
			<7607 6390 5436 5144 5080 5065>,
			<7693 6529 5461 5143 5077 5062>,
			<7815 6728 5517 5151 5081 5067>,
			<7892 6838 5536 5156 5086 5071>,
			<7879 6865 5544 5162 5090 5075>,
			<7945 6985 5593 5173 5096 5083>,
			<8150 7183 5659 5177 5099 5082>,
			<8419 7425 5720 5173 5085 5069>,
			<8964 7700 5796 5172 5086 5071>,
			<10688 8054 5991 5197 5091 5077>,
			<16139 9207 6347 5234 5108 5095>,
			<16139 9207 6347 5234 5108 5095>,
			<16139 9207 6347 5234 5108 5095>;
	};

};
